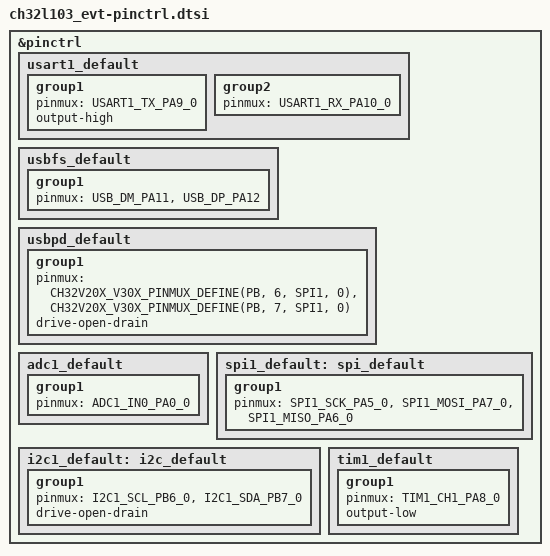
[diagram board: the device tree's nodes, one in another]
/*
 * Copyright (c) 2026 Scott King
 *
 * SPDX-License-Identifier: Apache-2.0
 */

#include <zephyr/dt-bindings/pinctrl/ch32v20x_30x-pinctrl.h>

/* USBFS pins are dedicated. Using ADC mux as a neutral placeholder
   that results in Analog Input configuration (CFGR = 0), which
   is recommended for USB pins when not managed by GPIO. */
#define USB_DM_PA11 CH32V20X_V30X_PINMUX_DEFINE(PA, 11, ADC1, 0)
#define USB_DP_PA12 CH32V20X_V30X_PINMUX_DEFINE(PA, 12, ADC1, 0)


&pinctrl {
	usart1_default: usart1_default {
		group1 {
			pinmux = <USART1_TX_PA9_0>;
			output-high;
		};
		group2 {
			pinmux = <USART1_RX_PA10_0>;
		};
	};

	usbfs_default: usbfs_default {
		group1 {
			pinmux = <USB_DM_PA11>, <USB_DP_PA12>;
		};
	};

    usbpd_default: usbpd_default {
        group1 {
            /* PB6 and PB7 are CC1 and CC2 */
            pinmux = <CH32V20X_V30X_PINMUX_DEFINE(PB, 6, SPI1, 0)>,
                     <CH32V20X_V30X_PINMUX_DEFINE(PB, 7, SPI1, 0)>;
            drive-open-drain; 
        };
    };

    adc1_default: adc1_default {
        group1 {
            pinmux = <ADC1_IN0_PA0_0>;
        };
    };

    spi1_default: spi_default {
        group1 {
            pinmux = <SPI1_SCK_PA5_0>, <SPI1_MOSI_PA7_0>, <SPI1_MISO_PA6_0>;
        };
    };

    i2c1_default: i2c_default {
        group1 {
            pinmux = <I2C1_SCL_PB6_0>, <I2C1_SDA_PB7_0>;
            drive-open-drain;
        };
    };

    tim1_default: tim1_default {
        group1 {
            pinmux = <TIM1_CH1_PA8_0>;
            output-low;
        };
    };
};
